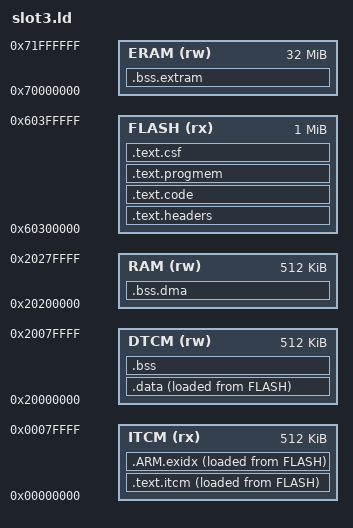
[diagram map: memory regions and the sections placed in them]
MEMORY
{
	ITCM (rx):  ORIGIN = 0x00000000, LENGTH = 512K
	DTCM (rw):  ORIGIN = 0x20000000, LENGTH = 512K
	RAM (rw):   ORIGIN = 0x20200000, LENGTH = 512K
	FLASH (rx): ORIGIN = 0x60300000, LENGTH = 1024K
	ERAM (rw):  ORIGIN = 0x70000000, LENGTH = 32768K
}

ENTRY(ImageVectorTable)

SECTIONS
{
	.text.headers : {
		KEEP(*(.flashconfig))
		FILL(0xFF)
		. = ORIGIN(FLASH) + 0x1000;
		KEEP(*(.ivt))
		KEEP(*(.bootdata))
		. = ALIGN(1024);
	} > FLASH

	.text.code : {
		KEEP(*(.startup))
		*(.flashmem*)
		. = ALIGN(4);
		KEEP(*(.init))
		__preinit_array_start = .;
		KEEP (*(.preinit_array))
		__preinit_array_end = .;
		__init_array_start = .;
		KEEP (*(.init_array))
		__init_array_end = .;
		. = ALIGN(4);
	} > FLASH

	.text.progmem : {
		*(.progmem*)
		/* String literals live in flash, not DTCM. The stock script folds
		   every .rodata* into .data (DTCM) for speed, but string text is
		   only ever read by printf and the display -- never from an ISR --
		   and with LTO it is a single 32 KB block. DTCM is 128 KB once
		   ITCM code takes 12 of the 16 FlexRAM banks; .data + .bss were
		   at 122 KB and the stack (whatever is left below _estack) had
		   fallen to 5.6 KB, which overflowed into the MPU guard at boot.
		   Flash is XIP through the cache; the only time it is unreadable
		   is during a LittleFS/EEPROM erase, and those run with IRQs off.
		   This rule must stay ahead of the .rodata* catch-all in .data:
		   the linker takes the first match. */
		*(.rodata.str1*)
		. = ALIGN(4);
	} > FLASH

	.text.itcm : {
		. = . + 32; /* MPU to trap NULL pointer deref */
		*(.fastrun)
		*(.text*)
		. = ALIGN(16);
	} > ITCM  AT> FLASH

	.ARM.exidx : {
		__exidx_start = .;
		*(.ARM.exidx* .ARM.extab.text* .gnu.linkonce.armexidx.*)
		__exidx_end = .;
	} > ITCM  AT> FLASH

	.data : {
		*(.endpoint_queue)   
		*(SORT_BY_ALIGNMENT(SORT_BY_NAME(.rodata*)))
		*(SORT_BY_ALIGNMENT(SORT_BY_NAME(.data*)))
		KEEP(*(.vectorsram))
	} > DTCM  AT> FLASH

	.bss ALIGN(4) : {
		*(SORT_BY_ALIGNMENT(SORT_BY_NAME(.bss*)))
		*(SORT_BY_ALIGNMENT(SORT_BY_NAME(COMMON)))
		. = ALIGN(32);
		. = . + 32; /* MPU to trap stack overflow */
	} > DTCM

	.bss.dma (NOLOAD) : {
		*(.hab_log)
		*(.dmabuffers)
		. = ALIGN(32);
	} > RAM

	.bss.extram (NOLOAD) : {
		*(SORT_BY_ALIGNMENT(SORT_BY_NAME(.externalram)))
		. = ALIGN(32);
	} > ERAM

	.text.csf : {
		FILL(0xFF)
		. = ALIGN(1024);
		KEEP(*(.csf))
		__text_csf_end = .;
	} > FLASH

	_stext = ADDR(.text.itcm);
	_etext = ADDR(.text.itcm) + SIZEOF(.text.itcm) + SIZEOF(.ARM.exidx);
	_stextload = LOADADDR(.text.itcm);

	_sdata = ADDR(.data);
	_edata = ADDR(.data) + SIZEOF(.data);
	_sdataload = LOADADDR(.data);

	_sbss = ADDR(.bss);
	_ebss = ADDR(.bss) + SIZEOF(.bss);

	_heap_start = ADDR(.bss.dma) + SIZEOF(.bss.dma);
	_heap_end = ORIGIN(RAM) + LENGTH(RAM);

	_extram_start = ADDR(.bss.extram);
	_extram_end = ADDR(.bss.extram) + SIZEOF(.bss.extram);

	_itcm_block_count = (SIZEOF(.text.itcm) + SIZEOF(.ARM.exidx) + 0x7FFF) >> 15;
	_flexram_bank_config = 0xAAAAAAAA | ((1 << (_itcm_block_count * 2)) - 1);
	_estack = ORIGIN(DTCM) + ((16 - _itcm_block_count) << 15);

	_flashimagelen = __text_csf_end - ORIGIN(FLASH);
	_teensy_model_identifier = 0x25;

    ASSERT((_flashimagelen) <= 0x100000, "CRITICAL: T41 boot slot overflows the 1024K limit!")

	/* The stack is not sized anywhere: it is whatever DTCM is left between
	   _ebss and _estack, and _estack itself moves in 32 KB steps with ITCM
	   code size. It had shrunk to 5.6 KB without anyone noticing until the
	   boot path faulted on the stack-guard MPU region. 16 KB is the floor:
	   the deepest measured use (a preset save with the verbose console
	   report) is about 3.5 KB, boot with audio init is more, and an
	   interrupt can arrive on top of either. */
	_stack_size = _estack - _ebss;
	ASSERT(_stack_size >= 0x4000, "CRITICAL: T41 stack below 16K -- DTCM is full; move data to DMAMEM or code to FLASHMEM")

	.debug_info     0 : { *(.debug_info) }
	.debug_abbrev   0 : { *(.debug_abbrev) }
	.debug_line     0 : { *(.debug_line) }
	.debug_frame    0 : { *(.debug_frame) }
	.debug_str      0 : { *(.debug_str) }
	.debug_loc      0 : { *(.debug_loc) }

}
